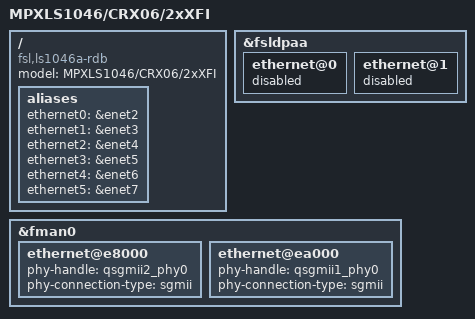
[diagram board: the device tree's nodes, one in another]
/*
 * Device Tree Include file for Freescale Layerscape-1046A family SoC.
 *
 * Copyright 2019 NXP
 * Copyright (C) 2019 MicroSys Electronics GmbH
 *
 * Mingkai Hu <mingkai.hu@nxp.com>
 *
 * This file is dual-licensed: you can use it either under the terms
 * of the GPLv2 or the X11 license, at your option. Note that this dual
 * licensing only applies to this file, and not this project as a
 * whole.
 *
 *  a) This library is free software; you can redistribute it and/or
 *     modify it under the terms of the GNU General Public License as
 *     published by the Free Software Foundation; either version 2 of the
 *     License, or (at your option) any later version.
 *
 *     This library is distributed in the hope that it will be useful,
 *     but WITHOUT ANY WARRANTY; without even the implied warranty of
 *     MERCHANTABILITY or FITNESS FOR A PARTICULAR PURPOSE.  See the
 *     GNU General Public License for more details.
 *
 * Or, alternatively,
 *
 *  b) Permission is hereby granted, free of charge, to any person
 *     obtaining a copy of this software and associated documentation
 *     files (the "Software"), to deal in the Software without
 *     restriction, including without limitation the rights to use,
 *     copy, modify, merge, publish, distribute, sublicense, and/or
 *     sell copies of the Software, and to permit persons to whom the
 *     Software is furnished to do so, subject to the following
 *     conditions:
 *
 *     The above copyright notice and this permission notice shall be
 *     included in all copies or substantial portions of the Software.
 *
 *     THE SOFTWARE IS PROVIDED "AS IS", WITHOUT WARRANTY OF ANY KIND,
 *     EXPRESS OR IMPLIED, INCLUDING BUT NOT LIMITED TO THE WARRANTIES
 *     OF MERCHANTABILITY, FITNESS FOR A PARTICULAR PURPOSE AND
 *     NONINFRINGEMENT. IN NO EVENT SHALL THE AUTHORS OR COPYRIGHT
 *     HOLDERS BE LIABLE FOR ANY CLAIM, DAMAGES OR OTHER LIABILITY,
 *     WHETHER IN AN ACTION OF CONTRACT, TORT OR OTHERWISE, ARISING
 *     FROM, OUT OF OR IN CONNECTION WITH THE SOFTWARE OR THE USE OR
 *     OTHER DEALINGS IN THE SOFTWARE.
 */

#include "mpxls1046_crx06.dtsi"

/ {
	model = "MPXLS1046/CRX06/2xXFI";
	compatible = "fsl,ls1046a-rdb", "fsl,ls1046a";

	aliases {
		ethernet0 = &enet2; /* fm1mac3 */
		ethernet1 = &enet3; /* fm1mac4 */
		ethernet2 = &enet4; /* fm1mac5 */
		ethernet3 = &enet5; /* fm1mac6 */
		ethernet4 = &enet6; /* fm1mac9 */
		ethernet5 = &enet7; /* fm1mac10 */
	};

};

&fsldpaa {

	ethernet@0 {
		status = "disabled";
	};

	ethernet@1 {
		status = "disabled";
	};

};

&fman0 {

	ethernet@e8000 {
		phy-handle = <&qsgmii2_phy0>;
		phy-connection-type = "sgmii";
		status = "okay";
	};

	ethernet@ea000 {
		phy-handle = <&qsgmii1_phy0>;
		phy-connection-type = "sgmii";
		status = "okay";
	};

};
